# Q32M210 register map
File version: 1.0
Registers are 32-bit, read-write, no defined reset value unless marked. A register's access mark holds for its fields unless they carry their own. Offsets are from the block's base; [hi:lo] are bit positions.

## PCM_Interface_Configuration_and_Control
Base 0x40000800
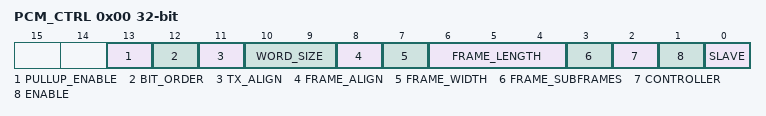
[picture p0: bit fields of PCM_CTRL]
0x00 PCM_CTRL — PCM Control
  [13] PULLUP_ENABLE — Configure the optional pull-up resistors for the PCM interface input pads
    0=PCM_PULLUP_DISABLE (Disconnect the pull-up resistors from the PCM input pads); 1=PCM_PULLUP_ENABLE (Connect the pull-up resistors to the PCM input pads)
  [12] BIT_ORDER — Select whether the data will be transmitted starting with the MSB or LSB
    0=PCM_BIT_ORDER_MSB_FIRST (PCM data is ordered from MSB to LSB); 1=PCM_BIT_ORDER_LSB_FIRST (PCM data is ordered from LSB to MSB)
  [11] TX_ALIGN — Select what bits to use for transmit data
    0=PCM_TX_ALIGN_MSB (Use MSBs of transmit buffer when word size is less that 32 bits); 1=PCM_TX_ALIGN_LSB (Use LSBs of transmit buffer when word size is less that 32 bits)
  [10:9] WORD_SIZE — Select the number of bits per PCM word
    0=PCM_WORD_SIZE_8 (Use 8-bits words); 1=PCM_WORD_SIZE_16 (Use 16-bits words); 2=PCM_WORD_SIZE_24 (Use 24-bits words); 3=PCM_WORD_SIZE_32 (Use 32-bits words)
  [8] FRAME_ALIGN — Align the PCM frame signal to the first/last bit
    0=PCM_FRAME_ALIGN_LAST (Align the PCM frame signal to the last bit of the frame); 1=PCM_FRAME_ALIGN_FIRST (Align the PCM frame signal to the first bit of the frame)
  [7] FRAME_WIDTH — Use a long/short PCM frame signal
    0=PCM_FRAME_WIDTH_SHORT (The PCM frame is high for one PCM clock period); 1=PCM_FRAME_WIDTH_LONG (The PCM frame is high for half of the frame length)
  [6:4] FRAME_LENGTH — Select the number of words per PCM frame
    0=PCM_FRAME_LENGTH_2 (PCM frames contain 2 words); 1=PCM_FRAME_LENGTH_4 (PCM frames contain 4 words); 2=PCM_FRAME_LENGTH_6 (PCM frames contain 6 words); 3=PCM_FRAME_LENGTH_8 (PCM frames contain 8 words); 4=PCM_FRAME_LENGTH_10 (PCM frames contain 10 words); 5=PCM_FRAME_LENGTH_12 (PCM frames contain 12 words); 6=PCM_FRAME_LENGTH_14 (PCM frames contain 14 words); 7=PCM_FRAME_LENGTH_16 (PCM frames contain 16 words)
  [3] FRAME_SUBFRAMES — Enable/disable use of PCM subframes
    0=PCM_SUBFRAMES_DISABLE (Disable the use of PCM subframes); 1=PCM_SUBFRAMES_ENABLE (Enable the use of PCM subframes)
  [2] CONTROLLER — Select whether data transfer will be controlled by the ARM Cortex-M3 processor or the DMA for PCM
    0=PCM_CONTROLLER_CM3 (The ARM Cortex-M3 controls data transfers using PCM); 1=PCM_CONTROLLER_DMA (The DMA controls data transfers using PCM)
  [1] ENABLE — Enable/disable the PCM interface
    0=PCM_DISABLE (Disable the PCM interface); 1=PCM_ENABLE (Enable the PCM interface)
  [0] SLAVE — Use the PCM interface as a master/slave
    0=PCM_SELECT_MASTER (Use the PCM interface in master mode); 1=PCM_SELECT_SLAVE (Use the PCM interface in slave mode)
0x04 PCM_TX_DATA — PCM Transmit Data
  [31:0] PCM_TX_DATA — Data to transmit over the PCM interface
0x08 PCM_RX_DATA — PCM Receive Data
  [31:0] PCM_RX_DATA — Data received from the PCM interface

## CRC_Generator_Control
Base 0x40000A00
0x00 CRC_CTRL — CRC Generator Control
  [0] BYTE_ORDER — Select the endianess for bytes added to the CRC
    0=CRC_BIG_ENDIAN (Bytes are added to the CRC in big-endian order); 1=CRC_LITTLE_ENDIAN (Bytes are added to the CRC in little-endian order)
0x04 CRC_DATA — CRC Generator Data
  [15:0] CURRENT_CRC — Current value of the CRC generator calculation. Set to 0xFFFF to initialize the CRC calculation.
    0xFFFF=CRC_INIT_VALUE (Initial value for the CRC CCITT calculation)
0x08 CRC_ADD_1 — CRC Generator - Add 1 Bit
  [0] CRC_ADD_1_BIT — Add one bit to the CRC calculation
0x0C CRC_ADD_8 — CRC Generator - Add 1 Byte
  [7:0] CRC_ADD_8 — Add one byte (eight bits) to the CRC calculation
0x10 CRC_ADD_16 — CRC Generator - Add 1 Half-word
  [15:0] CRC_ADD_16 — Add one half-word (16 bits) to the CRC calculation
0x14 CRC_ADD_24 — CRC Generator - Add 3 Bytes
  [23:0] CRC_ADD_24_BITS — Add three bytes (24 bits) to the CRC calculation
0x18 CRC_ADD_32 — CRC Generator - Add 1 Word
  [31:0] CRC_ADD_32 — Add one word (32 bits) to the CRC calculation
